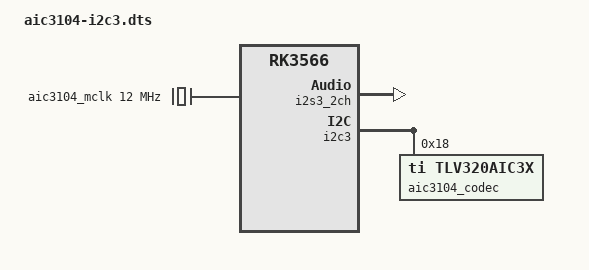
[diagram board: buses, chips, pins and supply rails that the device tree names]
/dts-v1/;
/plugin/;

/*
 * Optional TLV320AIC3104 audio codec on the Pollen Robotics RPI Robot HAT,
 * connected to the Radxa Zero 3W's hardware I2C3 bus.
 *
 * Pair this audio-only overlay with the generic sensor-bus overlay:
 *
 *     overlays=i2c3-qwiic aic3104-i2c3
 *
 * setup-board.sh provisions i2c3-qwiic whether or not this HAT is fitted.
 * The codec overlay only adds the codec and I2S sound card to that bus.
 */

/ {
    compatible = "radxa,zero-3w", "rockchip,rk3566";

    fragment@0 {
        target = <&i2s3_2ch>;
        __overlay__ {
            status = "okay";
        };
    };

    fragment@1 {
        target-path = "/";
        __overlay__ {
            aic3104_mclk: aic3104-mclk {
                compatible = "fixed-clock";
                #clock-cells = <0>;
                clock-frequency = <12000000>;
            };
        };
    };

    fragment@2 {
        target = <&i2c3>;
        __overlay__ {
            #address-cells = <1>;
            #size-cells = <0>;

            /*
             * Same generic "ti,tlv320aic3x" compatible as the Pi
             * overlay (not "ti,tlv320aic3104") so the driver exposes
             * the identical mixer-control set on both boards and
             * aic3104-init.sh works unchanged.
             */
            aic3104_codec: codec@18 {
                compatible = "ti,tlv320aic3x";
                reg = <0x18>;
                #sound-dai-cells = <0>;
                clocks = <&aic3104_mclk>;
                clock-names = "mclk";
                status = "okay";
            };
        };
    };

    fragment@3 {
        target-path = "/";
        __overlay__ {
            /* Card name "aic3104" matches the Pi so the runtime's
             * plughw:aic3104 / amixer -c aic3104 work on both. */
            sound-aic3104 {
                compatible = "simple-audio-card";
                simple-audio-card,name = "aic3104";
                simple-audio-card,format = "i2s";
                simple-audio-card,bitclock-master = <&aic3104_cpu_dai>;
                simple-audio-card,frame-master = <&aic3104_cpu_dai>;

                aic3104_cpu_dai: simple-audio-card,cpu {
                    sound-dai = <&i2s3_2ch>;
                    /* Pin the I2S mclk to 256*48000. No mclk-fs on
                     * the card: with mclk-fs, simple-card would
                     * override the codec's sysclk with fs-derived
                     * values that don't match the real 12 MHz MCLK,
                     * detuning the codec PLL. */
                    system-clock-frequency = <12288000>;
                };

                simple-audio-card,codec {
                    sound-dai = <&aic3104_codec>;
                };
            };
        };
    };
};
